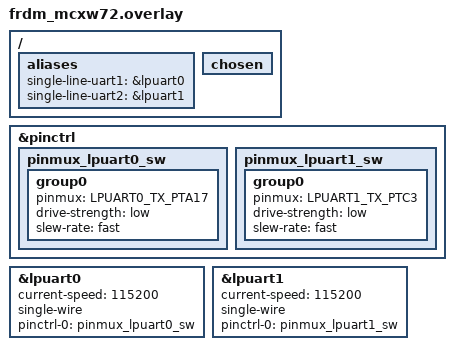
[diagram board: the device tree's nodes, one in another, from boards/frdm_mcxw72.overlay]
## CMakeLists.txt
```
# SPDX-License-Identifier: Apache-2.0

cmake_minimum_required(VERSION 3.28.0)
find_package(Zephyr REQUIRED HINTS $ENV{ZEPHYR_BASE})
project(uart_nxp_single_wire)

target_sources(app PRIVATE src/main.c)
```

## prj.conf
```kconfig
# Copyright 2026 NXP
# SPDX-License-Identifier: Apache-2.0

CONFIG_SERIAL=y
CONFIG_UART_CONSOLE=n
```

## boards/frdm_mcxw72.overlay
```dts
/*
 * Copyright 2026 NXP
 *
 * SPDX-License-Identifier: Apache-2.0
 */

/ {
	aliases {
		single-line-uart1 = &lpuart0;
		single-line-uart2 = &lpuart1;
	};

	chosen {
		/* Both UARTs are used by the sample, so neither can be the console. */
		/delete-property/ zephyr,console;
		/delete-property/ zephyr,shell-uart;
	};
};

&pinctrl {
	pinmux_lpuart0_sw: pinmux_lpuart0_sw {
		group0 {
			pinmux = <LPUART0_TX_PTA17>;
			drive-strength = "low";
			slew-rate = "fast";
		};
	};

	pinmux_lpuart1_sw: pinmux_lpuart1_sw {
		group0 {
			pinmux = <LPUART1_TX_PTC3>;
			drive-strength = "low";
			slew-rate = "fast";
		};
	};
};

&lpuart0 {
	status = "okay";
	current-speed = <115200>;
	single-wire;
	pinctrl-0 = <&pinmux_lpuart0_sw>;
	pinctrl-names = "default";
};

&lpuart1 {
	status = "okay";
	current-speed = <115200>;
	single-wire;
	pinctrl-0 = <&pinmux_lpuart1_sw>;
	pinctrl-names = "default";
};
```

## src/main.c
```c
/*
 * Copyright 2026 NXP
 *
 * SPDX-License-Identifier: Apache-2.0
 */

#include <zephyr/device.h>
#include <zephyr/devicetree.h>
#include <zephyr/drivers/uart.h>
#include <zephyr/kernel.h>

#define SINGLE_WIRE_UART1_NODE DT_ALIAS(single_line_uart1)
#define SINGLE_WIRE_UART2_NODE DT_ALIAS(single_line_uart2)

static const struct device *const single_wire_uart1 = DEVICE_DT_GET(SINGLE_WIRE_UART1_NODE);
static const struct device *const single_wire_uart2 = DEVICE_DT_GET(SINGLE_WIRE_UART2_NODE);

int main(void)
{
	unsigned char received;

	if (!device_is_ready(single_wire_uart1) || !device_is_ready(single_wire_uart2)) {
		return 0;
	}

	while (true) {
		uart_poll_out(single_wire_uart1, 'a');

		/* Allow the byte to be transmitted before reading it. */
		k_sleep(K_MSEC(50));
		(void)uart_poll_in(single_wire_uart2, &received);

		uart_poll_out(single_wire_uart2, 'b');

		/* Allow the byte to be transmitted before reading it. */
		k_sleep(K_MSEC(50));
		(void)uart_poll_in(single_wire_uart1, &received);

		k_sleep(K_SECONDS(2));
	}

	return 0;
}
```
